# STM32U585 register map
File version: 1.4
CPU: CM33 r0p1, little endian, MPU, FPU, 4 interrupt priority bits
Registers are 32-bit, read-write, reset 0x0 unless marked. A register's access mark holds for its fields unless they carry their own. Offsets are from the block's base; [hi:lo] are bit positions; 'fields as' and 'values as' point back to an identical list.

## CORDIC — CORDIC Co-processor
Base 0x40021000
Same registers: SEC_CORDIC 0x50021000
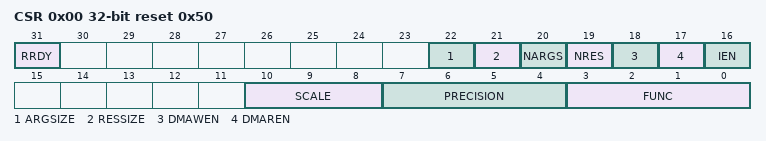
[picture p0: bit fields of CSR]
0x00 CSR access per field reset 0x50 — CORDIC Control Status register
  [31] RRDY ro — Result ready flag
  [22] ARGSIZE rw — Width of input data
  [21] RESSIZE rw — Width of output data
  [20] NARGS rw — Number of arguments expected by the CORDIC_WDATA register
  [19] NRES rw — Number of results in the CORDIC_RDATA register
  [18] DMAWEN rw — Enable DMA write channel
  [17] DMAREN rw — Enable DMA read channel
  [16] IEN rw — Enable interrupt
  [10:8] SCALE rw — Scaling factor
  [7:4] PRECISION rw — Precision required (number of iterations)
  [3:0] FUNC rw — Function
0x04 WDATA wo — FMAC Write Data register
  [31:0] ARG — Function input arguments
0x08 RDATA ro — FMAC Read Data register
  [31:0] RES — Function result

## OPAMP — Operational amplifiers
Base 0x46005000
Same registers: SEC_OPAMP 0x56005000
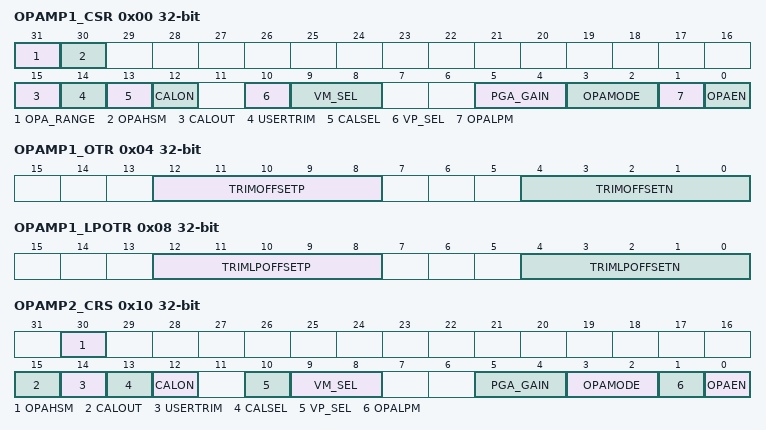
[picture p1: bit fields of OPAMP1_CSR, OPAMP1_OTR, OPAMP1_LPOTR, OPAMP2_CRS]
0x00 OPAMP1_CSR access per field — OPAMP1 control/status register
  [31] OPA_RANGE rw — OPAMP range setting This bit must be set before enabling the OPAMP and this bit affects all OPAMP instances.
  [30] OPAHSM rw — OPAMP high-speed mode This bit is effective for both normal and low-power modes.
  [15] CALOUT ro — OPAMP calibration output During the calibration mode, the offset is trimmed when this signal toggles.
  [14] USERTRIM rw — ‘factory’ or ‘user’ offset trimmed values selection This bit is active for normal and low-power modes.
  [13] CALSEL rw — Calibration selection
  [12] CALON rw — Calibration mode enable
  [10] VP_SEL rw — Non-inverted input selection
  [9:8] VM_SEL rw — Inverting input selection These bits are used only when OPAMODE = 00, 01 or 10. 1x: inverting input not externally connected
  [5:4] PGA_GAIN rw — OPAMP programmable amplifier gain value
  [3:2] OPAMODE rw — OPAMP PGA mode 00 and 01: internal PGA disabled
  [1] OPALPM rw — OPAMP low-power mode The OPAMP must be disabled to change this configuration.
  [0] OPAEN rw — OPAMP enable
0x04 OPAMP1_OTR (reset mask 0xFFFF0000) — OPAMP1 offset trimming register in normal mode
  [12:8] TRIMOFFSETP — Trim for PMOS differential pairs
  [4:0] TRIMOFFSETN — Trim for NMOS differential pairs
0x08 OPAMP1_LPOTR (reset mask 0xFFFF0000) — OPAMP1 offset trimming register in low-power mode
  [12:8] TRIMLPOFFSETP — Low-power mode trim for PMOS differential pairs
  [4:0] TRIMLPOFFSETN — Low-power mode trim for NMOS differential pairs
0x10 OPAMP2_CRS access per field — OPAMP2 control/status register
  [30] OPAHSM rw — OPAMP high-speed mode This bit is effective for both normal and high-speed modes.
  [15] CALOUT ro — OPAMP calibration output During calibration mode, the offset is trimmed when this signal toggles.
  [14] USERTRIM rw — ‘factory’ or ‘user’ offset trimmed values selection This bit is active for normal and low-power modes.
  [13] CALSEL rw — Calibration selection
  [12] CALON rw — Calibration mode enable
  [10] VP_SEL rw — Non inverted input selection
  [9:8] VM_SEL rw — Inverting input selection These bits are used only when OPAMODE = 00, 01 or 10. in PGA mode for filtering) 1x: inverting input not externally connected
  [5:4] PGA_GAIN rw — OPAMP programmable amplifier gain value
  [3:2] OPAMODE rw — OPAMP PGA mode 00 and 01: internal PGA disabled
  [1] OPALPM rw — OPAMP low-power mode The OPAMP must be disabled to change this configuration.
  [0] OPAEN rw — OPAMP enable
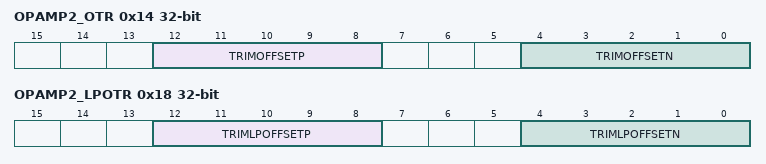
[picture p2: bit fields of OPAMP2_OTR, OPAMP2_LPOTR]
0x14 OPAMP2_OTR (reset mask 0xFFFF0000) — OPAMP2 offset trimming register in normal mode
  fields as OPAMP1_OTR
0x18 OPAMP2_LPOTR (reset mask 0xFFFF0000) — OPAMP2 offset trimming register in low-power mode
  fields as OPAMP1_LPOTR

## DLYBOS1 — The delay block (DLYB) is used to generate an output clock that is dephased from the input clock
Base 0x420CF000
Same registers: DLYBSD1 0x420C8400, DLYBSD2 0x420C8800, DLYBOS2 0x420CF400, SEC_DLYBSD1 0x520C8400, SEC_DLYBSD2 0x520C8800, SEC_DLYBOS1 0x520CF000, SEC_DLYBOS2 0x520CF400
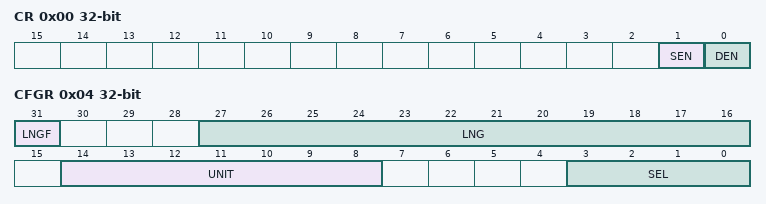
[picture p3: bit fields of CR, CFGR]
0x00 CR — control register
  [1] SEN — OPALPM
  [0] DEN — Operational amplifier Enable
0x04 CFGR access per field — configuration register
  [31] LNGF ro, [27:16] LNG ro, [14:8] UNIT rw, [3:0] SEL rw
